VERSION ""

NS_ :

BS_:

BU_: XXX

BO_ 947 MISC_REPORT: 8 XXX
 SG_ PHARES : 20|1@0+ (1,0) [0|1] "" XXX
 SG_ FOG_FRONT : 56|1@0+ (1,0) [0|1] "" XXX
 SG_ FOG_REAR : 1|1@0+ (1,0) [0|1] "" XXX
 SG_ IGNITION : 36|1@0+ (1,0) [0|3] "" XXX
 SG_ LEFT_MIRROR_MOTOR : 42|1@0+ (1,0) [0|1] "" XXX
 SG_ RIGHT_LIGHT_ENABLED : 62|1@0+ (1,0) [0|1] "" XXX
 SG_ RIGHT_LIGHT : 63|1@0+ (1,0) [0|1] "" XXX
 SG_ LEFT_LIGHT : 8|1@0+ (1,0) [0|1] "" XXX
 SG_ MOTEUR_OFF : 4|1@0+ (1,0) [0|1] "" XXX
 SG_ STARTED : 6|1@0+ (1,0) [0|1] "" XXX
 SG_ ENGINE_ON : 11|1@0+ (1,0) [0|1] "" XXX
 SG_ START_BUTTON : 7|1@0+ (1,0) [0|1] "" XXX
 SG_ _TBD3 : 28|1@0+ (1,0) [0|1] "" XXX
 SG_ LEFT_LIGHT_ENABLED : 9|1@0+ (1,0) [0|1] "" XXX
 SG_ LEFT_MIRROR_LIGHT : 54|1@0+ (1,0) [0|1] "" XXX
 SG_ RIGHT_MIRROR_LIGHT : 35|1@0+ (1,0) [0|1] "" XXX
 SG_ _RIGHT_BLIS : 41|1@0+ (1,0) [0|1] "" XXX
 SG_ _DAY_NIGHT : 40|1@0+ (1,0) [0|1] "" XXX
 SG_ _MOTEUR_RETRO_DROIT : 24|1@0+ (1,0) [0|1] "" XXX
 SG_ NEW_SIGNAL_1 : 34|1@0+ (1,0) [0|1] "" XXX
 SG_ NEW_SIGNAL_2 : 33|1@0+ (1,0) [0|1] "" XXX
 SG_ PASSENGER_DOOR_OPENED : 60|1@0+ (1,0) [0|1] "" XXX
 SG_ DRIVER_DOOR_OPENED : 61|1@0+ (1,0) [0|1] "" XXX
 SG_ DOORS_CLOSED : 57|1@0+ (1,0) [0|1] "" XXX
 SG_ _DOORS : 18|1@0+ (1,0) [0|1] "" XXX
 SG_ DOORS_REPORT : 0|1@0+ (1,0) [0|1] "" XXX
 SG_ _DAY : 14|1@0+ (1,0) [0|1] "" XXX
 SG_ _NIGHT : 15|1@0+ (1,0) [0|1] "" XXX
 SG_ VEILLEUSES_ON : 25|1@0+ (1,0) [0|1] "" XXX
 SG_ LIGHTS_ON : 2|1@0+ (1,0) [0|1] "" XXX
 SG_ VEILLEUSES : 21|1@0+ (1,0) [0|1] "" XXX

BO_ 357 BRAKE_PEDAL: 8 XXX
 SG_ ACC_ENABLED : 8|1@0+ (1,0) [0|3] "" XXX
 SG_ ACC_STATUS : 16|1@0+ (1,0) [0|255] "" XXX
 SG_ ACC_BRAKE : 41|1@0+ (1,0) [0|1] "" XXX
 SG_ USER_BRAKE : 5|1@0+ (1,0) [0|15] "" XXX
 SG_ REPORT_USER_BRAKE : 36|1@0+ (1,0) [0|1] "" XXX
 SG_ ACC_SET_SPEED : 23|8@0+ (1,0) [0|63] "" XXX
 SG_ NEW_SIGNAL_1 : 15|2@0+ (1,0) [0|3] "" XXX
 SG_ NEW_SIGNAL_2 : 10|2@0+ (1,0) [0|1] "" XXX
 SG_ NEW_SIGNAL_3 : 13|2@0+ (1,0) [0|3] "" XXX
 SG_ _ACC_SPEED_PLUS : 11|1@0+ (1,0) [0|63] "" XXX

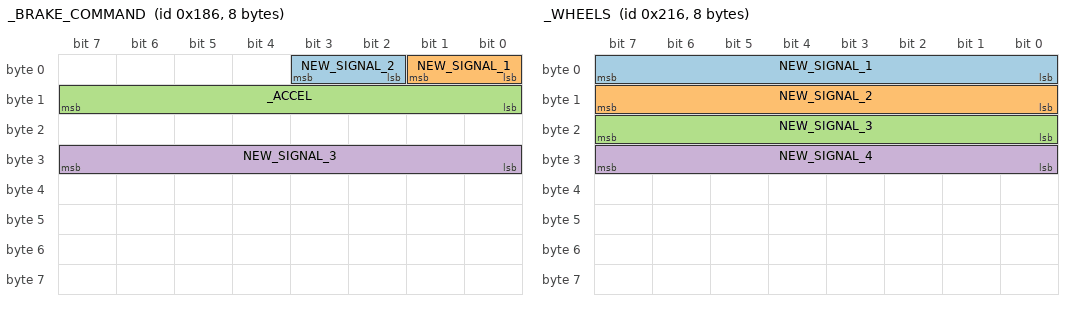
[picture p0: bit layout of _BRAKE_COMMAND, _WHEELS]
BO_ 390 _BRAKE_COMMAND: 8 XXX
 SG_ NEW_SIGNAL_2 : 2|2@1- (1,0) [0|3] "" XXX
 SG_ NEW_SIGNAL_1 : 0|2@1+ (1,0) [0|15] "" XXX
 SG_ _ACCEL : 8|8@1- (1,0) [0|4095] "" XXX
 SG_ NEW_SIGNAL_3 : 31|8@0+ (1,0) [0|255] "" XXX

BO_ 377 _UPTIME: 8 XXX
 SG_ COUNTER : 47|24@0+ (1,0) [0|8388607] "" XXX

BO_ 534 _WHEELS: 8 XXX
 SG_ NEW_SIGNAL_1 : 7|8@0+ (1,0) [0|255] "" XXX
 SG_ NEW_SIGNAL_2 : 15|8@0+ (1,0) [0|255] "" XXX
 SG_ NEW_SIGNAL_3 : 23|8@0+ (1,0) [0|255] "" XXX
 SG_ NEW_SIGNAL_4 : 31|8@0+ (1,0) [0|255] "" XXX

BO_ 532 NEW_MSG_4: 8 XXX
 SG_ NEW_SIGNAL_1 : 48|4@1+ (1,0) [0|15] "" XXX
 SG_ NEW_SIGNAL_2 : 63|4@0+ (1,0) [0|15] "" XXX

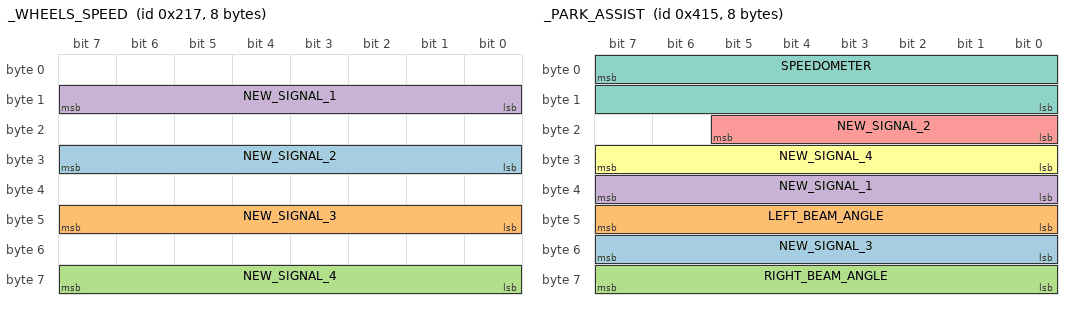
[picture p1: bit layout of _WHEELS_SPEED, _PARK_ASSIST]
BO_ 535 _WHEELS_SPEED: 8 XXX
 SG_ NEW_SIGNAL_2 : 31|8@0+ (1,0) [0|255] "" XXX
 SG_ NEW_SIGNAL_3 : 47|8@0+ (1,0) [0|255] "" XXX
 SG_ NEW_SIGNAL_4 : 63|8@0+ (1,0) [0|255] "" XXX
 SG_ NEW_SIGNAL_1 : 15|8@0+ (1,0) [0|255] "" XXX

BO_ 560 GEAR: 8 XXX
 SG_ GEAR_CURRENT : 7|4@0- (1,0) [0|65535] "" XXX
 SG_ SHIFTER : 9|3@1+ (1,0) [0|15] "" XXX

BO_ 514 _SPEED: 8 XXX
 SG_ _REAR_MODE : 0|4@1+ (1,0) [0|15] "" XXX
 SG_ SPEED : 48|16@0+ (0.01,0) [0|65535] "" XXX

BO_ 1045 _PARK_ASSIST: 8 XXX
 SG_ NEW_SIGNAL_3 : 55|8@0+ (1,0) [0|255] "" XXX
 SG_ LEFT_BEAM_ANGLE : 47|8@0- (1,0) [0|255] "" XXX
 SG_ RIGHT_BEAM_ANGLE : 63|8@0- (1,0) [0|255] "" XXX
 SG_ NEW_SIGNAL_1 : 39|8@0+ (1,0) [0|255] "" XXX
 SG_ NEW_SIGNAL_2 : 21|6@0+ (1,0) [0|63] "" XXX
 SG_ NEW_SIGNAL_4 : 31|8@0- (1,0) [0|31] "" XXX
 SG_ SPEEDOMETER : 7|16@0+ (0.01,5) [0|255] "" XXX

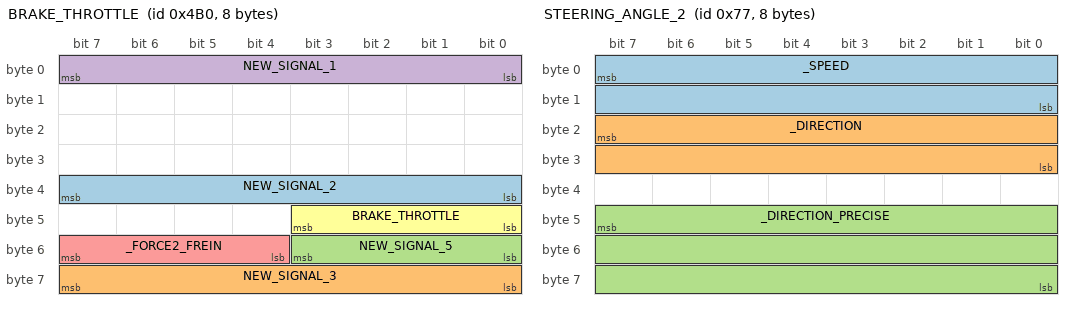
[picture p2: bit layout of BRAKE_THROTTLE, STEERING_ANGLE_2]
BO_ 1200 BRAKE_THROTTLE: 8 XXX
 SG_ NEW_SIGNAL_2 : 39|8@0+ (1,0) [0|255] "" XXX
 SG_ NEW_SIGNAL_3 : 63|8@0- (1,0) [0|255] "" XXX
 SG_ NEW_SIGNAL_5 : 51|4@0+ (1,0) [0|1] "" XXX
 SG_ NEW_SIGNAL_1 : 7|8@0+ (1,0) [0|255] "" XXX
 SG_ _FORCE2_FREIN : 55|4@0+ (1,0) [0|15] "" XXX
 SG_ BRAKE_THROTTLE : 43|4@0+ (1,0) [0|1] "" XXX

BO_ 145 _STEERING_ANGLE: 8 XXX
 SG_ NEW_SIGNAL_2 : 39|16@0+ (1,0) [0|16777215] "" XXX
 SG_ _DIRECTION : 23|16@0+ (1,0) [0|65535] "" XXX

BO_ 516 RPM: 8 XXX
 SG_ RPM : 29|15@0+ (1,0) [0|6000] "RPM" XXX
 SG_ NEW_SIGNAL_1 : 16|4@1+ (1,0) [0|15] "" XXX

BO_ 119 STEERING_ANGLE_2: 8 XXX
 SG_ _SPEED : 7|16@0+ (1,0) [0|255] "" XXX
 SG_ _DIRECTION : 23|16@0+ (1,0) [0|65535] "" XXX
 SG_ _DIRECTION_PRECISE : 47|24@0+ (1,0) [0|255] "" XXX

BO_ 120 NEW_MSG_7: 8 XXX

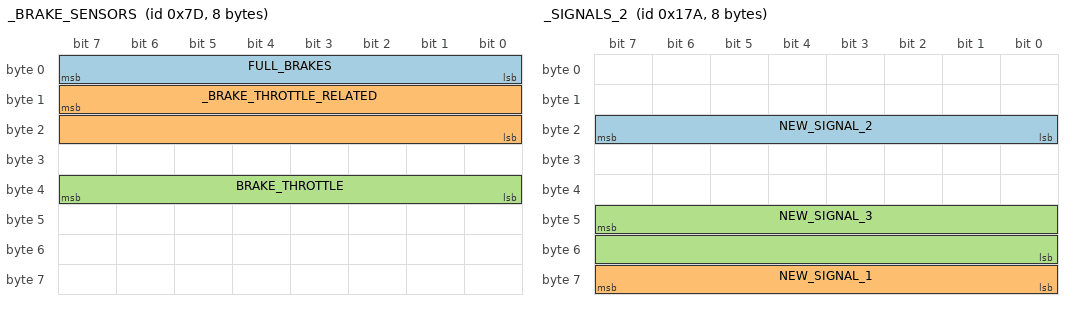
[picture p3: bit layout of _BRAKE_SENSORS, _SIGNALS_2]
BO_ 125 _BRAKE_SENSORS: 8 XXX
 SG_ FULL_BRAKES : 7|8@0+ (1,0) [0|255] "" XXX
 SG_ _BRAKE_THROTTLE_RELATED : 15|16@0+ (1,0) [0|65535] "" XXX
 SG_ BRAKE_THROTTLE : 39|8@0+ (1,0) [0|255] "" XXX

BO_ 378 _SIGNALS_2: 8 XXX
 SG_ NEW_SIGNAL_2 : 23|8@0+ (1,0) [0|255] "" XXX
 SG_ NEW_SIGNAL_1 : 63|8@0- (1,0) [0|65535] "" XXX
 SG_ NEW_SIGNAL_3 : 47|16@0+ (1,0) [0|65535] "" XXX

BO_ 391 _SIGNALS: 8 XXX
 SG_ _VOLTAGE2 : 47|8@0+ (1,0) [0|255] "" XXX
 SG_ _SIGNAL_1 : 15|8@0+ (1,0) [0|255] "" XXX

BO_ 1034 NEW_MSG_8: 8 XXX

BO_ 1076 NEW_MSG_9: 8 XXX
 SG_ _SIGNAL_1 : 15|8@0+ (1,0) [0|255] "" XXX

BO_ 133 TORQUE: 8 XXX
 SG_ TORQUE : 7|16@0+ (1,0) [0|255] "" XXX
 SG_ NEW_SIGNAL_1 : 63|8@0+ (1,0) [0|255] "" XXX

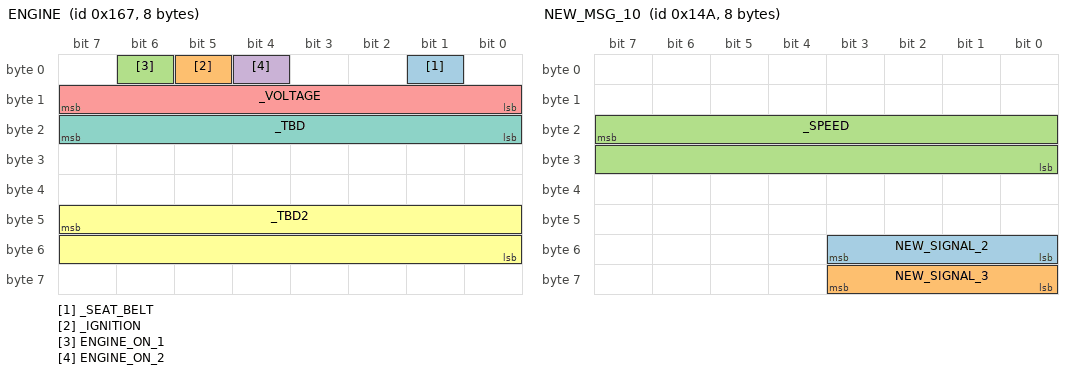
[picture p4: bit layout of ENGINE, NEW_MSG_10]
BO_ 359 ENGINE: 8 XXX
 SG_ _SEAT_BELT : 1|1@0+ (1,0) [0|255] "" XXX
 SG_ _IGNITION : 5|1@0+ (1,0) [0|15] "" XXX
 SG_ ENGINE_ON_1 : 6|1@0+ (1,0) [0|1] "" XXX
 SG_ ENGINE_ON_2 : 4|1@0+ (1,0) [0|1] "" XXX
 SG_ _VOLTAGE : 15|8@0+ (1,0) [0|255] "" XXX
 SG_ _TBD2 : 47|16@0+ (1,0) [0|65535] "" XXX
 SG_ _TBD : 23|8@0+ (1,0) [0|255] "" XXX

BO_ 950 _RECURRENT: 8 XXX

BO_ 330 NEW_MSG_10: 8 XXX
 SG_ NEW_SIGNAL_2 : 51|4@0+ (1,0) [0|65535] "" XXX
 SG_ NEW_SIGNAL_3 : 56|4@1+ (1,0) [0|15] "" XXX
 SG_ _SPEED : 23|16@0+ (1,0) [0|255] "" XXX

BO_ 118 PARK_ASSIST: 8 XXX
 SG_ TORQUE : 7|16@0+ (1,0) [0|65535] "" XXX
 SG_ DRIVE_OR_REVERSE : 17|1@1+ (1,0) [0|7] "" XXX

BO_ 570 NEW_MSG_3: 8 XXX

BO_ 146 NEW_MSG_12: 8 XXX
 SG_ EW_SIGNAL_1 : 40|16@1- (1,0) [0|16777215] "" XXX

BO_ 949 NEW_MSG_13: 8 XXX
 SG_ NEW_SIGNAL_1 : 7|8@0+ (1,0) [0|255] "" XXX
 SG_ NEW_SIGNAL_2 : 23|16@0+ (1,0) [0|255] "" XXX
 SG_ NEW_SIGNAL_3 : 56|3@0+ (1,0) [0|255] "" XXX

BO_ 817 DRIVE_TIME: 8 XXX
 SG_ DRIVE_TIME_SECONDS : 23|16@0+ (1,0) [0|65535] "" XXX

BO_ 939 NEW_MSG_14: 8 XXX

BO_ 818 DRIVE_TIME_IN_SECONDS: 8 XXX
 SG_ DRIVE_TIME_IN_SECONDS : 23|16@0+ (1,0) [0|65535] "" XXX
 SG_ _DOOR_LOCK_PRESSED : 15|8@0+ (1,0) [0|127] "" XXX

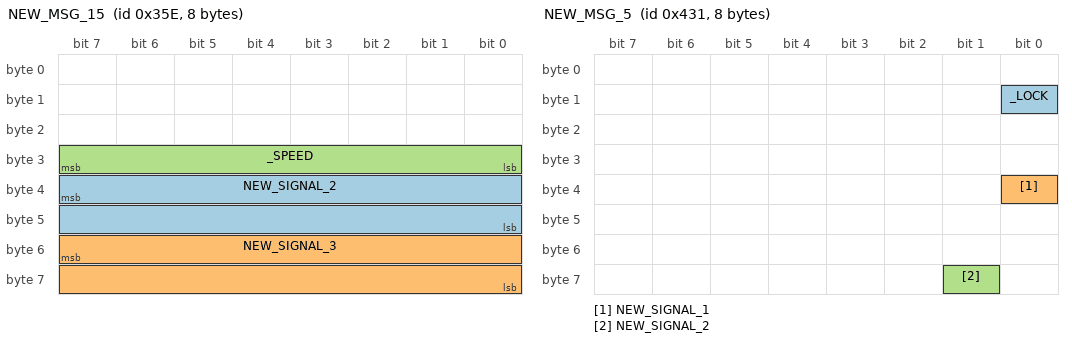
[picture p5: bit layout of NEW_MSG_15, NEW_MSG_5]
BO_ 862 NEW_MSG_15: 8 XXX
 SG_ NEW_SIGNAL_2 : 39|16@0+ (1,0) [0|65535] "" XXX
 SG_ NEW_SIGNAL_3 : 55|16@0+ (1,0) [0|65535] "" XXX
 SG_ _SPEED : 31|8@0+ (1,0) [0|255] "" XXX

BO_ 984 LKAS_RELATED: 8 XXX
 SG_ _LKAS_ON_OFF : 55|4@0+ (1,0) [0|15] "" XXX

BO_ 130 BUTTONS_STEERING_WHEEL: 8 XXX

BO_ 934 NEW_MSG_1: 8 XXX
 SG_ NEW_SIGNAL_1 : 23|8@0+ (1,0) [0|255] "" XXX
 SG_ _SHIFT : 31|8@0+ (1,0) [0|255] "" XXX

BO_ 1073 NEW_MSG_5: 8 XXX
 SG_ _LOCK : 8|1@0+ (1,0) [0|1] "" XXX
 SG_ NEW_SIGNAL_1 : 32|1@0+ (1,0) [0|1] "" XXX
 SG_ NEW_SIGNAL_2 : 57|1@0+ (1,0) [0|1] "" XXX

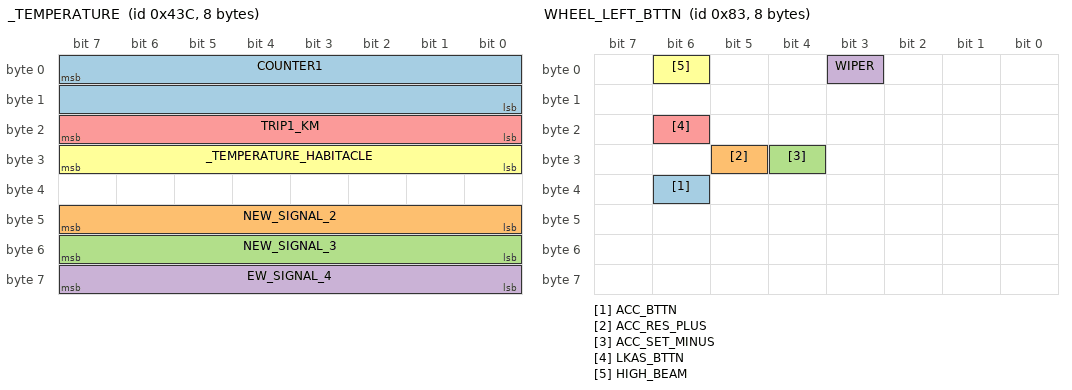
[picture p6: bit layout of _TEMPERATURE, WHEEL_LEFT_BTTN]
BO_ 1084 _TEMPERATURE: 8 XXX
 SG_ COUNTER1 : 7|16@0+ (1,0) [0|65535] "" XXX
 SG_ NEW_SIGNAL_2 : 47|8@0+ (1,0) [0|16777215] "" XXX
 SG_ NEW_SIGNAL_3 : 55|8@0+ (1,0) [0|255] "" XXX
 SG_ EW_SIGNAL_4 : 63|8@0+ (1,0) [0|255] "" XXX
 SG_ TRIP1_KM : 23|8@0+ (1,0) [0|65535] "" XXX
 SG_ _TEMPERATURE_HABITACLE : 31|8@0+ (1,0) [0|255] "" XXX

BO_ 131 WHEEL_LEFT_BTTN: 8 XXX
 SG_ ACC_BTTN : 38|1@0+ (1,0) [0|1] "" XXX
 SG_ ACC_RES_PLUS : 29|1@0+ (1,0) [0|1] "" XXX
 SG_ ACC_SET_MINUS : 28|1@0+ (1,0) [0|1] "" XXX
 SG_ WIPER : 3|1@0+ (1,0) [0|1] "" XXX
 SG_ LKAS_BTTN : 22|1@0+ (1,0) [0|1] "" XXX
 SG_ HIGH_BEAM : 6|1@0+ (1,0) [0|1] "" XXX

BO_ 394 NEW_MSG_6: 8 XXX
 SG_ _AUTO_BREAK_ENABLED : 24|1@0+ (1,0) [0|1] "" XXX

BO_ 531 EPB_STATE: 8 XXX
 SG_ EPB_STATE : 29|1@0+ (1,0) [0|1] "" XXX

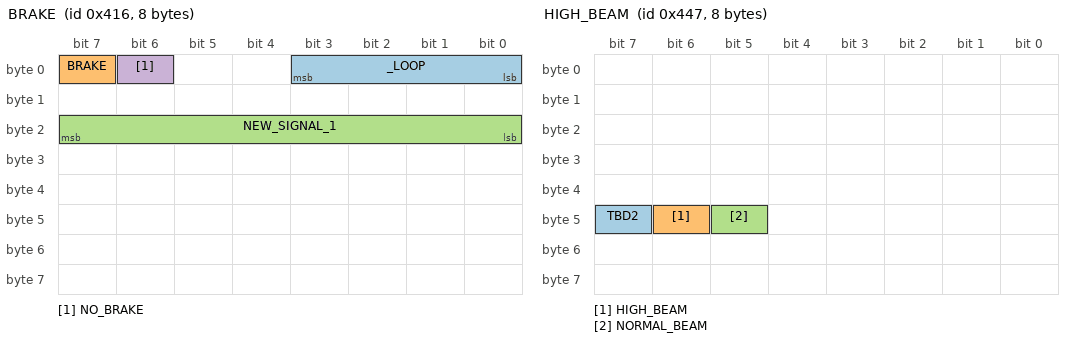
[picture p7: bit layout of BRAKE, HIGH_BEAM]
BO_ 1046 BRAKE: 8 XXX
 SG_ _LOOP : 0|4@1+ (1,0) [0|15] "" XXX
 SG_ BRAKE : 7|1@0+ (1,0) [0|1] "" XXX
 SG_ NEW_SIGNAL_1 : 23|8@0+ (1,0) [0|255] "" XXX
 SG_ NO_BRAKE : 6|1@0+ (1,0) [0|1] "" XXX

BO_ 1108 _NI: 8 XXX

BO_ 1082 _NI: 8 XXX

BO_ 1215 NEW_MSG_16: 8 XXX

BO_ 358 ODOMETER: 8 XXX
 SG_ ODOMETER : 31|24@0+ (0.1,0) [0|65535] "" XXX

BO_ 1430 _NI: 8 XXX

BO_ 1438 _NI: 8 XXX

BO_ 1459 _NI: 8 XXX

BO_ 1461 _NI: 8 XXX

BO_ 1058 _COUNTER: 8 XXX
 SG_ INCREMENTAL : 23|16@0+ (1,0) [0|65535] "" XXX

BO_ 973 NEW_MSG_17: 8 XXX
 SG_ NEW_SIGNAL_1 : 7|8@0+ (1,0) [0|255] "" XXX
 SG_ NEW_SIGNAL_2 : 23|8@0+ (1,0) [0|255] "" XXX

BO_ 936 _SIGNAL: 8 XXX
 SG_ NEW_SIGNAL_1 : 23|16@0+ (1,0) [0|65535] "" XXX
 SG_ _SIGNAL_2 : 0|1@0+ (1,0) [0|1] "" XXX

BO_ 512 NEW_MSG_18: 8 XXX
 SG_ NEW_SIGNAL_2 : 47|8@0- (1,0) [0|15] "" XXX
 SG_ NEW_SIGNAL_1 : 31|8@0- (1,0) [0|255] "" XXX

BO_ 578 NEW_MSG_19: 8 XXX
 SG_ NEW_SIGNAL_1 : 31|8@0- (1,0) [0|255] "" XXX

BO_ 1095 HIGH_BEAM: 8 XXX
 SG_ TBD2 : 47|1@0+ (1,0) [0|1] "" XXX
 SG_ HIGH_BEAM : 46|1@0+ (1,0) [0|15] "" XXX
 SG_ NORMAL_BEAM : 45|1@0+ (1,0) [0|1] "" XXX

BO_ 1057 NEW_MSG_11: 8 XXX

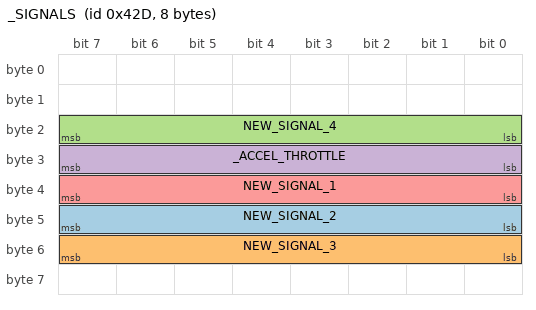
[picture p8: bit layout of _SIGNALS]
BO_ 1069 _SIGNALS: 8 XXX
 SG_ NEW_SIGNAL_2 : 47|8@0+ (1,0) [0|255] "" XXX
 SG_ NEW_SIGNAL_3 : 55|8@0+ (1,0) [0|255] "" XXX
 SG_ NEW_SIGNAL_4 : 23|8@0+ (1,0) [0|255] "" XXX
 SG_ _ACCEL_THROTTLE : 31|8@0+ (1,0) [0|65535] "" XXX
 SG_ NEW_SIGNAL_1 : 39|8@0+ (1,0) [0|255] "" XXX

CM_ SG_ 947 PHARES "ON OFF";
CM_ SG_ 947 _RIGHT_BLIS "BLIS ?";
CM_ SG_ 357 ACC_ENABLED "0:disabled 1:enabled";
CM_ SG_ 357 ACC_STATUS "0:inactive 1:active";
CM_ SG_ 560 GEAR_CURRENT "0:N -2:R 1:1 2:2 etc...";
CM_ SG_ 560 SHIFTER "0:P 1:R 2:N 3:D 4:S";
CM_ SG_ 1045 SPEEDOMETER "REAL SPEED";
CM_ SG_ 118 DRIVE_OR_REVERSE "1:D 0:R";
CM_ SG_ 818 _DOOR_LOCK_PRESSED "+1 when pressed +1 when depressed";
CM_ SG_ 862 _SPEED "related to vehicle move";

CM_ "CHFFR_METRIC 342 STEER_ANGLE STEER_ANGLE 0.36 180; CHFFR_METRIC 380 ENGINE_RPM ENGINE_RPM 1 0; CHFFR_METRIC 804 ENGINE_TEMPERATURE ENGINE_TEMPERATURE 1 0";
